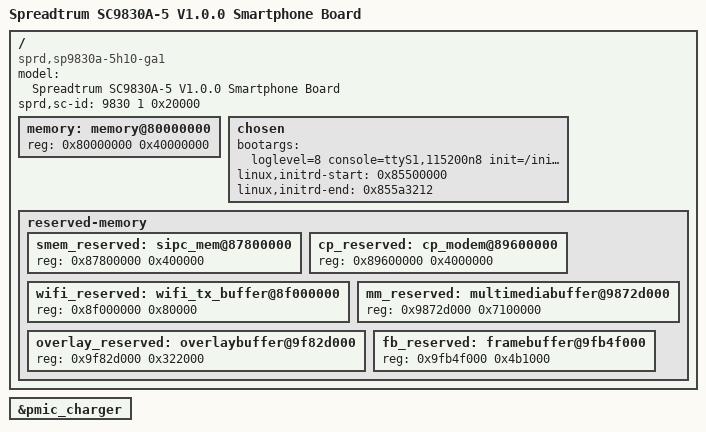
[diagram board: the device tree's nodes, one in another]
/*
 * Spreadtrum SC9830A-5 h/w ver. 1.0.0 smartphone board DTS file
 *
 * Copyright (C) 2015-2016, Spreadtrum Communications Inc.
 *
 * This file is licensed under a dual GPLv2 or X11 license.
 */

#include "sp9830a-common.dtsi"

/ {
	model = "Spreadtrum SC9830A-5 V1.0.0 Smartphone Board";

	compatible = "sprd,sp9830a-5h10-ga1", "sprd,sc9830";

	sprd,sc-id = <9830 1 0x20000>;

	memory: memory@80000000 {
		device_type = "memory";
		reg = <0x80000000 0x40000000>;
	};

	chosen {
		bootargs = "loglevel=8 console=ttyS1,115200n8 init=/init root=/dev/ram0 rw androidboot.hardware=sc9830";
		linux,initrd-start = <0x85500000>;
		linux,initrd-end = <0x855a3212>;
	};

	reserved-memory {
		#address-cells = <1>;
		#size-cells = <1>;
		ranges;

		smem_reserved: sipc_mem@87800000 {
			reg = <0x87800000 0x400000>;
		};

		cp_reserved: cp_modem@89600000 {
			reg = <0x89600000 0x4000000>;
		};

		wifi_reserved: wifi_tx_buffer@8f000000 {
			reg = <0x8f000000 0x80000>;
		};

		mm_reserved: multimediabuffer@9872d000{
			reg = <0x9872d000 0x7100000>;
		};

		overlay_reserved: overlaybuffer@9f82d000{
			reg = <0x9f82d000 0x322000>;
		};

		fb_reserved: framebuffer@9fb4f000{
			reg = <0x9fb4f000 0x4b1000>;
		};
	};
};

&pmic_charger{
	status = "okay";
};
